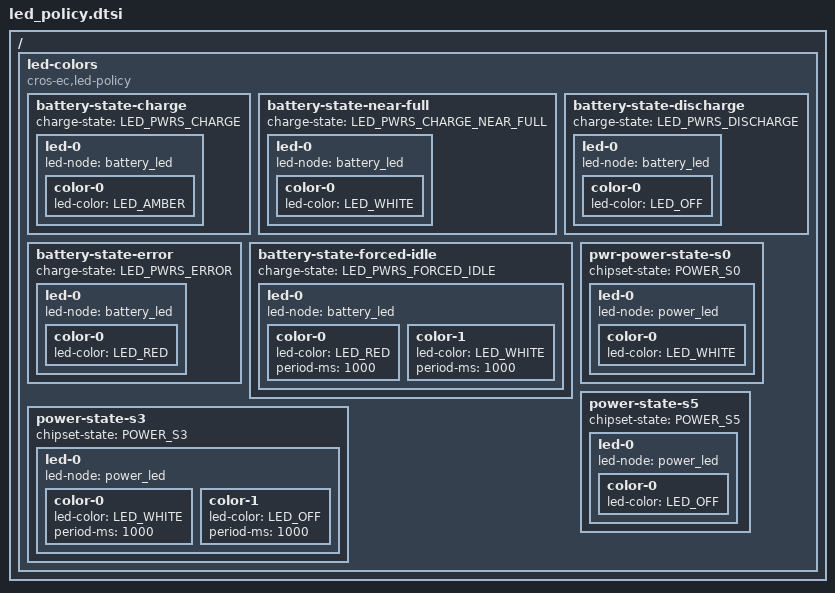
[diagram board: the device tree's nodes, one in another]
#include <dt-bindings/battery.h>

/ {
	led-colors {
		compatible = "cros-ec,led-policy";

		battery-state-charge {
			charge-state = "LED_PWRS_CHARGE";

			led-0 {
				led-node = <&battery_led>;

				color-0 {
					led-color = "LED_AMBER";
				};
			};
		};

		battery-state-near-full {
			charge-state = "LED_PWRS_CHARGE_NEAR_FULL";

			led-0 {
				led-node = <&battery_led>;

				color-0 {
					led-color = "LED_WHITE";
				};
			};
		};

		battery-state-discharge {
			charge-state = "LED_PWRS_DISCHARGE";

			led-0 {
				led-node = <&battery_led>;

				color-0 {
					led-color = "LED_OFF";
				};
			};
		};

		battery-state-error {
			charge-state = "LED_PWRS_ERROR";

			led-0 {
				led-node = <&battery_led>;

				color-0 {
					led-color = "LED_RED";
				};
			};
		};

		/* force idle mode */
		battery-state-forced-idle {
			charge-state = "LED_PWRS_FORCED_IDLE";

			led-0 {
				led-node = <&battery_led>;

				/* Red 1 sec, White 1 sec */
				color-0 {
					led-color = "LED_RED";
					period-ms = <1000>;
				};

				color-1 {
					led-color = "LED_WHITE";
					period-ms = <1000>;
				};
			};
		};

		pwr-power-state-s0 {
			chipset-state = "POWER_S0";

			led-0 {
				led-node = <&power_led>;

				color-0 {
					led-color = "LED_WHITE";
				};
			};
		};

		power-state-s3 {
			chipset-state = "POWER_S3";

			led-0 {
				led-node = <&power_led>;

				/* white LED - on 1 sec, off 1 sec */
				color-0 {
					led-color = "LED_WHITE";
					period-ms = <1000>;
				};

				color-1 {
					led-color = "LED_OFF";
					period-ms = <1000>;
				};
			};
		};

		power-state-s5 {
			chipset-state = "POWER_S5";

			led-0 {
				led-node = <&power_led>;

				color-0 {
					led-color = "LED_OFF";
				};
			};
		};
	};
};
